AUTOSAR XML (schema 4-3-0)
package /CollisionDetectionBSW/Services/ComM
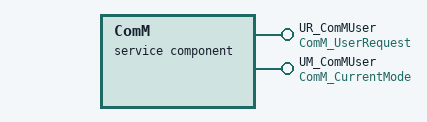
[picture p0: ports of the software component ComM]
  service sw component type ComM
    provide port UR_ComMUser: provided-interface=ComM_UserRequest
    provide port UM_ComMUser: provided-interface=ComM_CurrentMode
    behavior ComMBehavior: data-type-mapping=ComMTypeMappings, handle-termination-and-restart=NO-SUPPORT, port-api-option{port-defined-argument-value{value=ComM_UserHandleType:0, value-type=ComM_UserHandleType}, port=UR_ComMUser}
      4 x operation invoked event:
        RequestComMode_UR_ComMUser_RequestComMode: start-on-event=RequestComMode, operation=UR_ComMUser.RequestComMode
        GetMaxComMode_UR_ComMUser_GetMaxComMode: start-on-event=GetMaxComMode, operation=UR_ComMUser.GetMaxComMode
        GetRequestedComMode_UR_ComMUser_GetRequestedComMode: start-on-event=GetRequestedComMode, operation=UR_ComMUser.GetRequestedComMode
        GetCurrentComMode_UR_ComMUser_GetCurrentComMode: start-on-event=GetCurrentComMode, operation=UR_ComMUser.GetCurrentComMode
      5 x runnable:
        ComM_MainFunction
          mode switch point modeSwitchPoint_ComM_MainFunction_UM_ComMUser_currentMode: mode-group=UM_ComMUser.currentMode
        RequestComMode: can-be-invoked-concurrently=true, symbol=ComM_RequestComMode
        GetMaxComMode: can-be-invoked-concurrently=true, symbol=ComM_GetMaxComMode
        GetRequestedComMode: can-be-invoked-concurrently=true, symbol=ComM_GetRequestedComMode
        GetCurrentComMode: can-be-invoked-concurrently=true, symbol=ComM_GetCurrentComMode
  swc implementation ComMImpl: programming-language=C, vendor-id=60, behavior=ComMBehavior
    code-descriptors:
      code src: artifact-descriptors=autosar-engineering-object={short-label=artifactDescriptor, category=artifactDescriptorCategory}
    resource consumption resourceConsumption
package /CollisionDetectionBSW/Services/EcuM
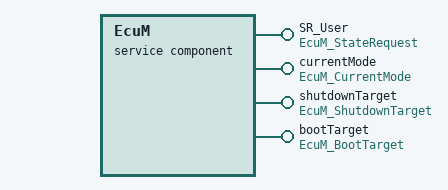
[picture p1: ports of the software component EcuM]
  service sw component type EcuM
    4 x provide port:
      SR_User: provided-interface=EcuM_StateRequest
      currentMode: provided-interface=EcuM_CurrentMode
      shutdownTarget: provided-interface=EcuM_ShutdownTarget
      bootTarget: provided-interface=EcuM_BootTarget
    behavior EcuMFixedBehavior: data-type-mapping=EcuMFixedTypeMappings, handle-termination-and-restart=NO-SUPPORT, port-api-option{port-defined-argument-value{value=EcuM_UserType:0, value-type=EcuM_UserType}, port=SR_User}
      9 x operation invoked event:
        RequestRUN_SR_User_RequestRUN: start-on-event=RequestRUN, operation=SR_User.RequestRUN
        ReleaseRUN_SR_User_ReleaseRUN: start-on-event=ReleaseRUN, operation=SR_User.ReleaseRUN
        RequestPOSTRUN_SR_User_RequestPOSTRUN: start-on-event=RequestPOSTRUN, operation=SR_User.RequestPOSTRUN
        ReleasePOSTRUN_SR_User_ReleasePOSTRUN: start-on-event=ReleasePOSTRUN, operation=SR_User.ReleasePOSTRUN
        SelectShutdownTarget_shutdownTarget_SelectShutdownTarget: start-on-event=SelectShutdownTarget, operation=shutdownTarget.SelectShutdownTarget
        GetShutdownTarget_shutdownTarget_GetShutdownTarget: start-on-event=GetShutdownTarget, operation=shutdownTarget.GetShutdownTarget
        GetLastShutdownTarget_shutdownTarget_GetLastShutdownTarget: start-on-event=GetLastShutdownTarget, operation=shutdownTarget.GetLastShutdownTarget
        SelectBootTarget_bootTarget_SelectBootTarget: start-on-event=SelectBootTarget, operation=bootTarget.SelectBootTarget
        GetBootTarget_bootTarget_GetBootTarget: start-on-event=GetBootTarget, operation=bootTarget.GetBootTarget
      10 x runnable:
        EcuM_MainFunction
          mode switch point modeSwitchPoint_EcuM_MainFunction_currentMode_currentMode: mode-group=currentMode.currentMode
        RequestRUN: can-be-invoked-concurrently=true, symbol=EcuM_RequestRUN
        ReleaseRUN: can-be-invoked-concurrently=true, symbol=EcuM_ReleaseRUN
        RequestPOSTRUN: can-be-invoked-concurrently=true, symbol=EcuM_RequestPOST_RUN
        ReleasePOSTRUN: can-be-invoked-concurrently=true, symbol=EcuM_ReleasePOST_RUN
        SelectShutdownTarget: can-be-invoked-concurrently=true, symbol=EcuM_SelectShutdownTarget
        GetShutdownTarget: can-be-invoked-concurrently=true, symbol=EcuM_GetShutdownTarget
        GetLastShutdownTarget: can-be-invoked-concurrently=true, symbol=EcuM_GetLastShutdownTarget
        SelectBootTarget: can-be-invoked-concurrently=true, symbol=EcuM_SelectBootTarget
        GetBootTarget: can-be-invoked-concurrently=true, symbol=EcuM_GetBootTarget
  swc implementation EcuMFixedImpl: programming-language=C, vendor-id=60, behavior=EcuMFixedBehavior
    code-descriptors:
      code src: artifact-descriptors=autosar-engineering-object={short-label=artifactDescriptor, category=artifactDescriptorCategory}
    resource consumption resourceConsumption
package /CollisionDetectionBSW/Services/BswM
  impl type ComMModeEnum: compu {0=COMM_NO_COMMUNICATION, 1=COMM_SILENT_COMMUNICATION, 2=COMM_FULL_COMMUNICATION}, implementation-data-type=uint8
  sender receiver interface ComMModeRequestInterface
    data requestedMode: type=ComMModeEnum
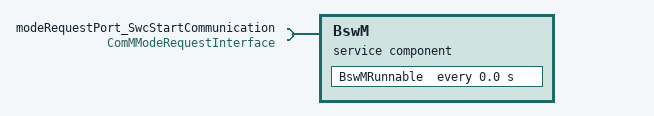
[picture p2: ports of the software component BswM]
  service sw component type BswM
    require port modeRequestPort_SwcStartCommunication: required-interface=ComMModeRequestInterface
    behavior BswMInternalBehavior: handle-termination-and-restart=NO-SUPPORT
      timing event BswMRunnableEvent: start-on-event=BswMRunnable, period=0.0
      runnable BswMRunnable: symbol=BswM_MainFunction
        data-receive-point-by-arguments:
          access dataReceivePoint_BswMRunnable_modeRequestPort_SwcStartCommunication_requestedMode: accessed-variable=modeRequestPort_SwcStartCommunication.requestedMode
  swc implementation BswMComponentImpl: programming-language=C, vendor-id=60, behavior=BswMInternalBehavior
    code-descriptors:
      code src: artifact-descriptors=autosar-engineering-object={short-label=artifactDescriptor, category=artifactDescriptorCategory}
    resource consumption resourceConsumption
package /CollisionDetectionBSW/Services/IoHwAb
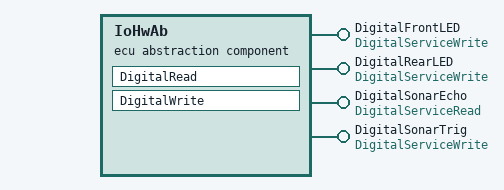
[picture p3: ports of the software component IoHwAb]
  ecu abstraction sw component type IoHwAb
    4 x provide port:
      DigitalFrontLED: provided-interface=DigitalServiceWrite
      DigitalRearLED: provided-interface=DigitalServiceWrite
      DigitalSonarEcho: provided-interface=DigitalServiceRead
      DigitalSonarTrig: provided-interface=DigitalServiceWrite
    behavior IoHwAbBehavior: handle-termination-and-restart=NO-SUPPORT
      4 x operation invoked event:
        DigitalRead_DigitalSonarEcho_Read: start-on-event=DigitalRead, operation=DigitalSonarEcho.Read
        DigitalWrite_DigitalFrontLED_Write: start-on-event=DigitalWrite, operation=DigitalFrontLED.Write
        DigitalWrite_DigitalRearLED_Write: start-on-event=DigitalWrite, operation=DigitalRearLED.Write
        DigitalWrite_DigitalSonarTrig_Write: start-on-event=DigitalWrite, operation=DigitalSonarTrig.Write
      port-api-options:
        {port-defined-argument-value{value=IoHwAb_SignalType_:0, value-type=IoHwAb_SignalType_}, port=DigitalFrontLED}
        {port-defined-argument-value{value=IoHwAb_SignalType_:1, value-type=IoHwAb_SignalType_}, port=DigitalRearLED}
        {port-defined-argument-value{value=IoHwAb_SignalType_:2, value-type=IoHwAb_SignalType_}, port=DigitalSonarEcho}
        {port-defined-argument-value{value=IoHwAb_SignalType_:3, value-type=IoHwAb_SignalType_}, port=DigitalSonarTrig}
      runnable DigitalRead: can-be-invoked-concurrently=true, symbol=IoHwAb_Digital_Read
      runnable DigitalWrite: can-be-invoked-concurrently=true, symbol=IoHwAb_Digital_Write
  swc implementation IoHwAbImpl: programming-language=C, vendor-id=60, behavior=IoHwAbBehavior
    code-descriptors:
      code src: artifact-descriptors=autosar-engineering-object={short-label=artifactDescriptor, category=artifactDescriptorCategory}
    resource consumption resourceConsumption
